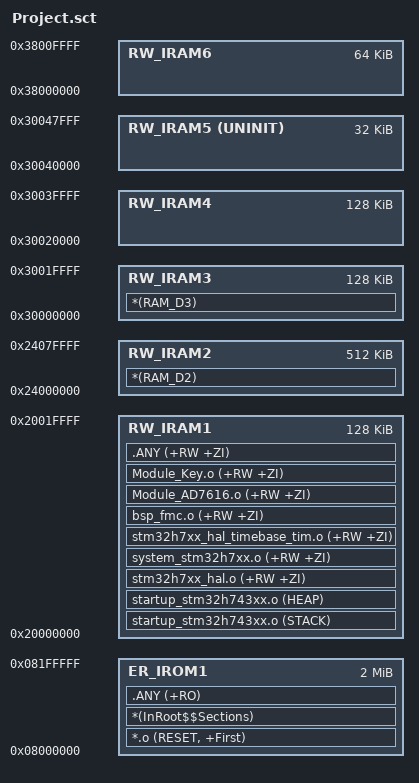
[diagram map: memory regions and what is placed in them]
; *************************************************************
; *** ARM Scatter Loading Description File (分散加载描述文件) ***
; *** 用于定义程序各段在 Flash 和 RAM 中的存储位置        ***
; *** STM32H743 完整内存映射 (2MB Flash + 1MB RAM)         ***
; *************************************************************

; ============================================================
; 加载域 (Load Region): LR_IROM1
; 起始地址: 0x08000000 (STM32H743 内部 Flash 起始地址)
; 大小: 0x00200000 (2MB)
; ============================================================
LR_IROM1 0x08000000 0x00200000  {
  
  ; ----------------------------------------------------------
  ; 执行域 (Execution Region): ER_IROM1
  ; 这是代码段（Flash 区域），存储程序的指令和只读数据
  ; 起始地址: 0x08000000
  ; 大小: 0x00200000 (2MB)
  ; ----------------------------------------------------------
  ER_IROM1 0x08000000 0x00200000  {
   
   ; *.o (RESET, +First)
   ; 含义: 将所有目标文件 (*.o) 中的 RESET 段放在最前面
   ; 作用: RESET 段包含中断向量表，ARM Cortex-M 规定中断向量表必须从 Flash 起始地址开始
   ; +First: 修饰符，表示该段必须放在执行域的最开始位置
   *.o (RESET, +First)
   
   ; *(InRoot$$Sections)
   ; 含义: 包含所有标记为 "Root" 的段（C 库的初始化代码）
   ; 作用: 这些是 C 运行时库必需的段，例如 __main、__scatterload 等
   ;       它们负责在 main() 函数执行前进行必要的初始化工作
   *(InRoot$$Sections)
   
   ; .ANY (+RO)
   ; 含义: 将所有模块的只读数据 (Read-Only) 段放入此执行域
   ; +RO: 只读段，包括：
   ;      - 代码段 (Code)
   ;      - 常量数据 (const 修饰的全局变量)
   ;      - 字符串常量
   ; .ANY: 通配符，表示所有模块
   .ANY (+RO)
  }
  
  ; ----------------------------------------------------------
  ; 执行域: RW_IRAM1
  ; 内存区域: DTCM (Data Tightly Coupled Memory)
  ; 起始地址: 0x20000000
  ; 大小: 0x00020000 (128KB)
  ; 域: CPU 内核直连
  ; 特点: 
  ;   - CPU 直连，访问速度最快（零等待）
  ;   - 无缓存一致性问题
  ;   - 不支持 DMA 访问
  ; 推荐用途: 
  ;   - 栈和堆
  ;   - 频繁访问的全局变量
  ;   - 中断服务程序中使用的变量
  ; ----------------------------------------------------------
  RW_IRAM1 0x20000000 0x00020000  {

  ;   startup_stm32h743xx.o (STACK)        ; 栈
  ;   startup_stm32h743xx.o (HEAP)         ; 堆

  ;   Module_AD7616.o ( +RW +ZI)  ; AD7616 驱动相关代码和数据
  ;   .ANY (+RW +ZI)
	; ; *(RAM_D1)  ; 支持自定义 section
  ; ; bsp_fmc.o (.+RO +RW +ZI)  ; FMC 驱动相关代码和数据
  

    ;  Priority 1：栈和堆（最频繁访问）
    startup_stm32h743xx.o (STACK)
    startup_stm32h743xx.o (HEAP)
    
    ;  Priority 2：HAL 核心变量（极高访问频率）
    stm32h7xx_hal.o (+RW +ZI)                    ; uwTick 等全局变量
    system_stm32h7xx.o (+RW +ZI)                 ; SystemCoreClock
    stm32h7xx_hal_timebase_tim.o (+RW +ZI)       ; TIM6 时基句柄
    
    ;  Priority 3：FMC 和 AD7616（关键驱动）
    bsp_fmc.o (+RW +ZI)
    Module_AD7616.o (+RW +ZI)
    
    ; ;  Priority 4：其他 BSP 驱动
    ; bsp_gpio.o (+RW +ZI)
    ; bsp_timer.o (+RW +ZI)
    ; bsp_dwt.o (+RW +ZI)
    
    ;  Priority 5：应用模块
    Module_Key.o (+RW +ZI)
    
    ;  Priority 6：剩余所有数据段（直到 DTCM 满）
    .ANY (+RW +ZI)
   
  }
  
  ; ----------------------------------------------------------
  ; 执行域: RW_IRAM2
  ; 内存区域: AXI SRAM (D1 域)  
  ; 起始地址: 0x24000000
  ; 大小: 0x00080000 (512KB)
  ; 域: D1 Domain (Domain 1)
  ; 特点: 
  ;   - STM32H7 中容量最大的单块 SRAM
  ;   - 支持 DMA1、DMA2、MDMA 访问
  ;   - 通过 AXI 总线连接，速度略慢于 DTCM
  ;   - 支持数据缓存 (D-Cache)
  ; 推荐用途: 
  ;   - 大数组和缓冲区
  ;   - DMA 数据缓冲区
  ;   - 图像数据、音频数据
  ;   - 通信协议缓冲区
  ; ----------------------------------------------------------
  RW_IRAM2 0x24000000 0x00080000  {
    *(RAM_D2)  ; 支持自定义 section
  ;  .ANY (+RW +ZI)
  }
  
  ; ----------------------------------------------------------
  ; 执行域: RW_IRAM3
  ; 内存区域: SRAM1 (D2 域)
  ; 起始地址: 0x30000000
  ; 大小: 0x00020000 (128KB)
  ; 域: D2 Domain (Domain 2)
  ; 特点: 
  ;   - 支持 DMA1、DMA2、BDMA 访问
  ;   - 外设访问友好（与外设在同一电源域）
  ;   - 可在 Stop 模式下保持数据
  ; 推荐用途: 
  ;   - DMA 缓冲区（特别是与外设通信）
  ;   - 低功耗模式下需要保持的数据
  ;   - 以太网、USB 等外设的缓冲区
  ; ----------------------------------------------------------
  RW_IRAM3 0x30000000 0x00020000  {
	*(RAM_D3)  ; 支持自定义 section
  ;  .ANY (+RW +ZI)
  }
  
  ; ----------------------------------------------------------
  ; 执行域: RW_IRAM4
  ; 内存区域: SRAM2 (D2 域)
  ; 起始地址: 0x30020000
  ; 大小: 0x00020000 (128KB)
  ; 域: D2 Domain (Domain 2)
  ; 特点: 
  ;   - 支持 DMA1、DMA2、BDMA 访问
  ;   - 外设访问友好
  ;   - 可在 Stop 模式下保持数据
  ; 推荐用途: 
  ;   - DMA 缓冲区
  ;   - 外设相关数据
  ;   - 低功耗模式数据保持
  ; ----------------------------------------------------------
  RW_IRAM4 0x30020000 0x00020000  {
  ;  .ANY (+RW +ZI)
  }
  
  ; ----------------------------------------------------------
  ; 执行域: RW_IRAM5
  ; 内存区域: SRAM3 (D2 域)
  ; 起始地址: 0x30040000
  ; 大小: 0x00008000 (32KB)
  ; 域: D2 Domain (Domain 2)
  ; 特点: 
  ;   - 支持 DMA1、DMA2、BDMA 访问
  ;   - 外设访问友好
  ;   - 可在 Stop 模式下保持数据
  ; 推荐用途: 
  ;   - DMA 缓冲区
  ;   - 外设相关数据
  ;   - 临时数据存储
  ; ----------------------------------------------------------
  RW_IRAM5 0x30040000 UNINIT 0x00008000  {
   
   ; EventRecorder.o (+ZI)
   ; 含义: Event Recorder 调试工具的数据段
   ; UNINIT 修饰符: 该区域在程序启动时不会被清零
   ; 原因: Event Recorder 需要在程序复位后保留之前的调试信息
  ;  EventRecorder.o (+ZI)
  ;  .ANY (+RW +ZI)
  }
  
  ; ----------------------------------------------------------
  ; 执行域: RW_IRAM6
  ; 内存区域: SRAM4 (D3 域)
  ; 起始地址: 0x38000000
  ; 大小: 0x00010000 (64KB)
  ; 域: D3 Domain (Domain 3 / SRD domain)
  ; 特点: 
  ;   - 位于 SmartRun Domain (低功耗域)
  ;   - 支持 BDMA 访问
  ;   - 在 D1 和 D2 域进入 Stop 模式时仍可工作
  ;   - 可配置为 ECC 保护
  ; 推荐用途: 
  ;   - 低功耗应用的关键数据
  ;   - BDMA 专用缓冲区
  ;   - 需要 ECC 保护的关键数据
  ;   - 备用电源域数据
  ; ----------------------------------------------------------
  RW_IRAM6 0x38000000 0x00010000  {
  ;  .ANY (+RW +ZI)
  }
  
  ; ----------------------------------------------------------
  ; 执行域: RW_IRAM7
  ; 内存区域: Backup SRAM (备份 SRAM)
  ; 起始地址: 0x38800000
  ; 大小: 0x00001000 (4KB)
  ; 域: Backup Domain (备份域)
  ; 特殊标记: UNINIT (不初始化)
  ; 特点: 
  ;   - 由 VBAT 供电，主电源掉电后仍可保持数据
  ;   - 在系统复位后数据不会丢失
  ;   - 需要使能 RCC 的 Backup Domain 时钟
  ; 推荐用途: 
  ;   - 掉电后需要保持的关键数据
  ;   - RTC 相关数据
  ;   - 系统状态标志
  ;   - Event Recorder (调试工具)
  ; ----------------------------------------------------------
;   RW_IRAM7 0x38800000 UNINIT 0x00001000  {
;    ; 也可以在此存放需要掉电保持的数据
;    ; 例如: backup_data.o (+RW +ZI)
;   }
}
